# SN32F240 register map
Vendor: SONiX Technology Co., Ltd.; Series: SN32F200; File version: 2.0
CPU: CM0 r0p0, little endian, no MPU, no FPU, 2 interrupt priority bits
Registers are 32-bit, read-write, reset 0x0 unless marked. A register's access mark holds for its fields unless they carry their own. Offsets are from the block's base; [hi:lo] are bit positions; {n}, {i} and the like mark numbered series.

## SN_ADC — ADC
Base 0x40026000
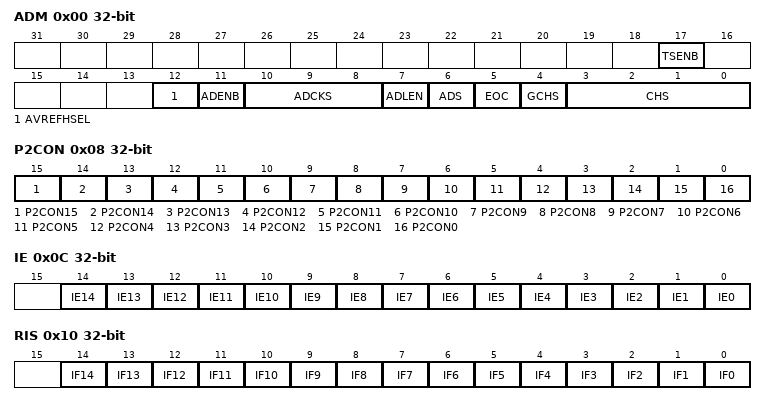
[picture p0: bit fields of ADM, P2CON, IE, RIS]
0x00 ADM (reset mask 0x31FF) — Offset:0x00 ADC Management Register
  [17] TSENB — Temperature sensor enable bit
    0=Disable Temperature sensor; 1=Enable Temperature sensor
  [12] AVREFHSEL — ADC high reference voltage source
    0=Interal VDD (P2.0 acts as GPIO or AIN0 pin); 1=External reference voltage (P2.0 acts as AVREFH pin)
  [11] ADENB — ADC enable
    0=Disable ADC; 1=Enable ADC
  [10:8] ADCKS — ADC clock source divider
    0=000b (ADC_PCLK/1); 1=001b (ADC_PCLK/2); 2=010b (ADC_PCLK/4); 3=011b (ADC_PCLK/8); 5=101b (ADC_PCLK/16); 6=110b (ADC_PCLK/32)
  [7] ADLEN — ADC resolution
    0=8-bit ADB; 1=12-bit ADB
  [6] ADS — ADC start control
    0=Stop (ADC stopped); 1=Start ADC conversion
  [5] EOC — ADC status
    0=Busy (ADC processing); 1=End (End of conversion)
  [4] GCHS — ADC global channel enable
    0=Disable AIN channel; 1=Enable AIN channel
  [3:0] CHS — ADC input channel
    {v}=AIN{v} (v=0..13); 14=Temperature sensor
0x04 ADB ro (reset mask 0xFFF) — Offset:0x04 ADC Data Register
0x08 P2CON ro — Offset:0x08 ADC Port 2 Control Register
  [15] P2CON15 — P2.15 Control
    0=Both (P2.15 can be analog input or digital I/O pin); 1=Analog (P2.15 is pure analog input, can't be digital I/O pin)
  [14] P2CON14 — P2.14 Control
    0=Both (P2.14 can be analog input or digital I/O pin); 1=Analog (P2.14 is pure analog input, can't be digital I/O pin)
  [13] P2CON13 — P2.13 Control
    0=Both (P2.13 can be analog input or digital I/O pin); 1=Analog (P2.13 is pure analog input, can't be digital I/O pin)
  [12] P2CON12 — P2.12 Control
    0=Both (P2.12 can be analog input or digital I/O pin); 1=Analog (P2.12 is pure analog input, can't be digital I/O pin)
  [11] P2CON11 — P2.11 Control
    0=Both (P2.11 can be analog input or digital I/O pin); 1=Analog (P2.11 is pure analog input, can't be digital I/O pin)
  [10] P2CON10 — P2.10 Control
    0=Both (P2.10 can be analog input or digital I/O pin); 1=Analog (P2.10 is pure analog input, can't be digital I/O pin)
  [9] P2CON9 — P2.9 Control
    0=Both (P2.9 can be analog input or digital I/O pin); 1=Analog (P2.9 is pure analog input, can't be digital I/O pin)
  [8] P2CON8 — P2.8 Control
    0=Both (P2.8 can be analog input or digital I/O pin); 1=Analog (P2.8 is pure analog input, can't be digital I/O pin)
  [7] P2CON7 — P2.7 Control
    0=Both (P2.7 can be analog input or digital I/O pin); 1=Analog (P2.7 is pure analog input, can't be digital I/O pin)
  [6] P2CON6 — P2.6 Control
    0=Both (P2.6 can be analog input or digital I/O pin); 1=Analog (P2.6 is pure analog input, can't be digital I/O pin)
  [5] P2CON5 — P2.5 Control
    0=Both (P2.5 can be analog input or digital I/O pin); 1=Analog (P2.5 is pure analog input, can't be digital I/O pin)
  [4] P2CON4 — P2.4 Control
    0=Both (P2.4 can be analog input or digital I/O pin); 1=Analog (P2.4 is pure analog input, can't be digital I/O pin)
  [3] P2CON3 — P2.3 Control
    0=Both (P2.3 can be analog input or digital I/O pin); 1=Analog (P2.3 is pure analog input, can't be digital I/O pin)
  [2] P2CON2 — P2.2 Control
    0=Both (P2.2 can be analog input or digital I/O pin); 1=Analog (P2.2 is pure analog input, can't be digital I/O pin)
  [1] P2CON1 — P2.1 Control
    0=Both (P2.1 can be analog input or digital I/O pin); 1=Analog (P2.1 is pure analog input, can't be digital I/O pin)
  [0] P2CON0 — P2.0 Control
    0=Both (P2.0 can be analog input or digital I/O pin); 1=Analog (P2.0 is pure analog input, can't be digital I/O pin)
0x0C IE (reset mask 0xEFFF) — Offset:0x0C ADC Interrupt Enable Register
  [n] IE{n} (n=0..14) — AIN{n} interrupt enable
    0=Disable AIN{n} interrupt; 1=Enable (ADC interrupt is triggered when AIN{n} completes ADC conversion)
0x10 RIS (reset mask 0xEFFF) — Offset:0x10 ADC Raw Interrupt Status Register
  [n] IF{n} (n=4..14) — AIN{n} interrupt flag
    0=No interrupt on AIN{n}; 1=Met interrupt requirements (AIN{n} completes ADC conversion)
  [3] IF3 — AIN0 interrupt flag
    0=No interrupt on AIN3; 1=Met interrupt requirements (AIN3 completes ADC conversion)
  [2] IF2 — AIN2 interrupt flag
    0=No interrupt on AIN2; 1=Met interrupt requirements (AIN2 completes ADC conversion)
  [1] IF1 — AIN1 interrupt flag
    0=No interrupt on AIN1; 1=Met interrupt requirements (AIN1 completes ADC conversion)
  [0] IF0 — AIN0 interrupt flag
    0=No interrupt on AIN0; 1=Met interrupt requirements (AIN0 completes ADC conversion)
